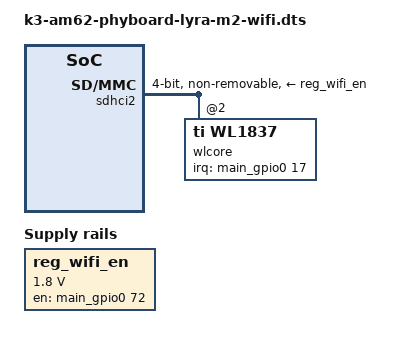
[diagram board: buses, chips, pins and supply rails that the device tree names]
// SPDX-License-Identifier: GPL-2.0
/*
 * Copyright (C) 2022 PHYTEC Messtechnik GmbH
 * Author: Wadim Egorov <w.egorov@phytec.de>
 */

/dts-v1/;
/plugin/;

#include <dt-bindings/gpio/gpio.h>
#include <dt-bindings/pinctrl/k3.h>

&{/} {
	reg_wifi_en: fixed-regulator-wifi-en {
		compatible = "regulator-fixed";
		regulator-name = "wifi_en";
		regulator-min-microvolt = <1800000>;
		regulator-max-microvolt = <1800000>;
		pinctrl-names = "default";
		pinctrl-0 = <&wifi_pins_default>;
		regulator-always-on;
		enable-active-high;
		gpio = <&main_gpio0 72 GPIO_ACTIVE_HIGH>;
	};
};

&main_pmx0 {
	main_mmc2_wifi_pins_default: main-mmc2-wifi-pins-default {
		pinctrl-single,pins = <
			AM62X_IOPAD(0x108, PIN_INPUT, 0) /* (D24) MMC2_DAT3 */
			AM62X_IOPAD(0x10c, PIN_INPUT, 0) /* (E23) MMC2_DAT2 */
			AM62X_IOPAD(0x110, PIN_INPUT, 0) /* (C25) MMC2_DAT1 */
			AM62X_IOPAD(0x114, PIN_INPUT, 0) /* (B24) MMC2_DAT0 */
			AM62X_IOPAD(0x118, PIN_INPUT, 0) /* (D25) MMC2_CLK */
			AM62X_IOPAD(0x120, PIN_INPUT, 0) /* (C24) MMC2_CMD */
			AM62X_IOPAD(0x11c, PIN_INPUT, 0) /* (#N/A) MMC2_CLKB */
		>;
	};

	wifi_pins_default: wifi-pins-default {
		pinctrl-single,pins = <
			/* WIFI_EN */
			AM62X_IOPAD(0x128, PIN_OUTPUT, 7) /* (B23) MMC2_SDWP.GPIO0_72 */
			/* WIFI_HOST_WAK */
			AM62X_IOPAD(0x044, PIN_INPUT, 7) /* (N24) GPMC0_AD2.GPIO0_17 */
		>;
	};
};

&sdhci2 {
	#address-cells = <1>;
	#size-cells = <0>;

	status = "okay";
	pinctrl-names = "default";
	pinctrl-0 = <&main_mmc2_wifi_pins_default>;
	vmmc-supply = <&reg_wifi_en>;
	bus-width = <4>;
	non-removable;

	ti,fails-without-test-cd;
	cap-power-off-card;
	keep-power-in-suspend;
	ti,driver-strength-ohm = <50>;
	assigned-clocks = <&k3_clks 157 158>;
	assigned-clock-parents = <&k3_clks 157 160>;

	wlcore: wlcore@2 {
		compatible = "ti,wl1837";
		reg = <2>;
		interrupt-parent = <&main_gpio0>;
		interrupts = <17 0>;
	};
};
